# ASR6601 register map
Vendor: ASR Microelectronics; Series: ASR6601; File version: 1.1
CPU: CM4 r0p1, little endian, no MPU, FPU, VTOR, 3 interrupt priority bits
Registers are 32-bit, read-write, no defined reset value unless marked. A register's access mark holds for its fields unless they carry their own. Offsets are from the block's base; [hi:lo] are bit positions; {n}, {i} and the like mark numbered series.

## RCC — Reset and clock control
Base 0x40000000
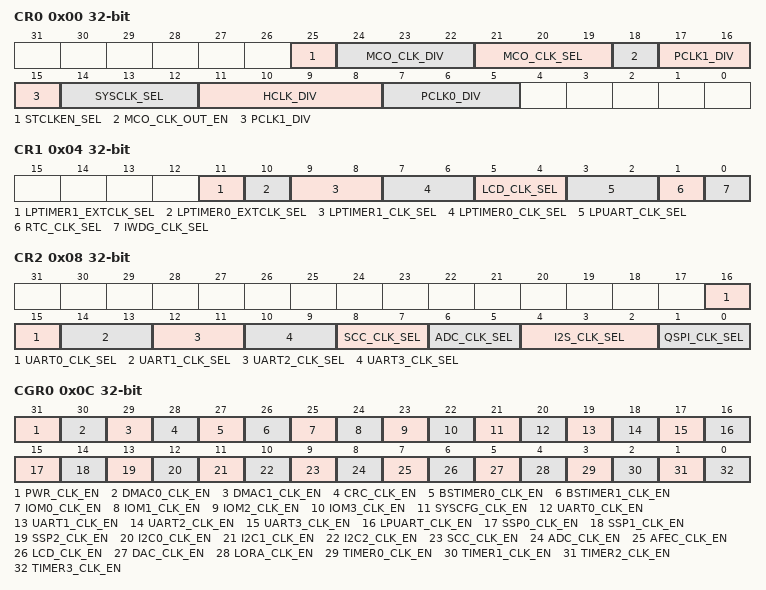
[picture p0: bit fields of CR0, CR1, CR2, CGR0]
0x00 CR0 — control register 0
  [25] STCLKEN_SEL
    1=RCO32K; 0=XO32K
  [24:22] MCO_CLK_DIV
    0=VALUE_1; 7=VALUE_16; 4=VALUE_2; 5=VALUE_4; 6=VALUE_8
  [21:19] MCO_CLK_SEL
    6=PLL; 0=RCO32K; 5=RCO48M; 2=RCO4M; 7=SYSCLCK; 3=XO24M; 1=XO32K; 4=XO32M
  [18] MCO_CLK_OUT_EN
  [17:15] PCLK1_DIV
    0=VALUE_1; 4=VALUE_16; 1=VALUE_2; 2=VALUE_4; 3=VALUE_8
  [14:12] SYSCLK_SEL
    3=PLL; 1=RCO32K; 7=RCO48M; 0=RCO48M_DIV2; 6=RCO4M; 4=XO24M; 2=XO32K; 5=XO32M
  [11:8] HCLK_DIV
    0=VALUE_1; 7=VALUE_128; 4=VALUE_16; 1=VALUE_2; 8=VALUE_256; 5=VALUE_32; 2=VALUE_4; 9=VALUE_512; 6=VALUE_64; 3=VALUE_8
  [7:5] PCLK0_DIV
    0=VALUE_1; 4=VALUE_16; 1=VALUE_2; 2=VALUE_4; 3=VALUE_8
0x04 CR1 — control register 1
  [11] LPTIMER1_EXTCLK_SEL
  [10] LPTIMER0_EXTCLK_SEL
  [9:8] LPTIMER1_CLK_SEL
    0=PCLK0; 3=RCO32K; 1=RCO4M; 2=XO32K
  [7:6] LPTIMER0_CLK_SEL
    0=PCLK0; 3=RCO32K; 1=RCO4M; 2=XO32K
  [5:4] LCD_CLK_SEL
    1=RCO32K; 2=RCO4M; 0=XO32K
  [3:2] LPUART_CLK_SEL
    1=RCO32K; 2=RCO4M; 0=XO32K
  [1] RTC_CLK_SEL
    1=RCO32K; 0=XO32K
  [0] IWDG_CLK_SEL
    1=RCO32K; 0=XO32K
0x08 CR2 — control register 2
  [16:15] UART0_CLK_SEL
    0=PCLK0; 1=RCO4M; 3=XO24M; 2=XO32K
  [14:13] UART1_CLK_SEL
    0=PCLK0; 1=RCO4M; 3=XO24M; 2=XO32K
  [12:11] UART2_CLK_SEL
    0=PCLK1; 1=RCO4M; 3=XO24M; 2=XO32K
  [10:9] UART3_CLK_SEL
    0=PCLK1; 1=RCO4M; 3=XO24M; 2=XO32K
  [8:7] SCC_CLK_SEL
    3=EXT; 0=PCLK1; 2=PLL; 1=SYSCLK
  [6:5] ADC_CLK_SEL
    0=PCLK1; 2=PLL; 3=RCO48M; 1=SYSCLK
  [4:2] I2S_CLK_SEL
    4=EXT_CLK; 0=PCLK0; 2=PLL; 1=XO24M; 3=XO32M
  [1:0] QSPI_CLK_SEL
    0=HCLK; 2=PLL; 1=SYSCLK
0x0C CGR0 — clock generation register 0
  [31] PWR_CLK_EN, [30] DMAC0_CLK_EN, [29] DMAC1_CLK_EN, [28] CRC_CLK_EN, [27] BSTIMER0_CLK_EN, [26] BSTIMER1_CLK_EN, [25-n] IOM{n}_CLK_EN (n=0..3), [21] SYSCFG_CLK_EN, [20-n] UART{n}_CLK_EN (n=0..3), [16] LPUART_CLK_EN, [15] SSP0_CLK_EN, [14] SSP1_CLK_EN, [13] SSP2_CLK_EN, [12] I2C0_CLK_EN, [11] I2C1_CLK_EN, [10] I2C2_CLK_EN, [9] SCC_CLK_EN, [8] ADC_CLK_EN, [7] AFEC_CLK_EN, [6] LCD_CLK_EN, [5] DAC_CLK_EN, [4] LORA_CLK_EN, [3-n] TIMER{n}_CLK_EN (n=0..3)
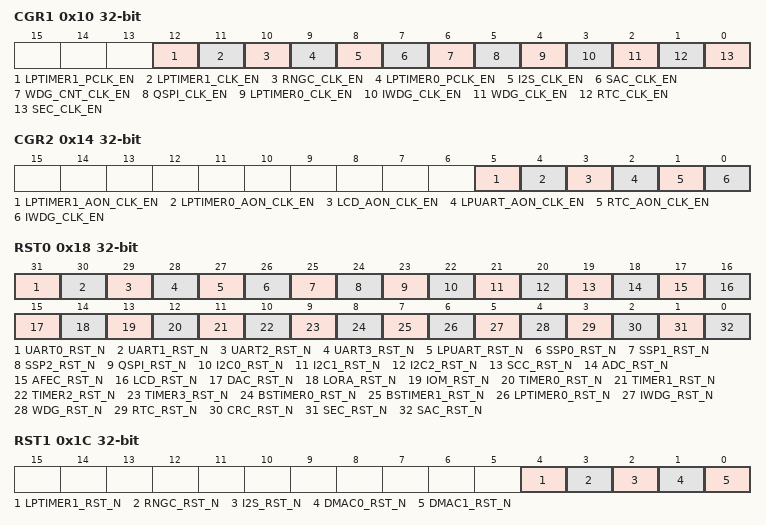
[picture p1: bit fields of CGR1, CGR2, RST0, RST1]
0x10 CGR1 — clock generation register 1
  [12] LPTIMER1_PCLK_EN, [11] LPTIMER1_CLK_EN, [10] RNGC_CLK_EN, [9] LPTIMER0_PCLK_EN, [8] I2S_CLK_EN, [7] SAC_CLK_EN, [6] WDG_CNT_CLK_EN, [5] QSPI_CLK_EN, [4] LPTIMER0_CLK_EN, [3] IWDG_CLK_EN, [2] WDG_CLK_EN, [1] RTC_CLK_EN, [0] SEC_CLK_EN
0x14 CGR2 — clock generation register 2
  [5] LPTIMER1_AON_CLK_EN, [4] LPTIMER0_AON_CLK_EN, [3] LCD_AON_CLK_EN, [2] LPUART_AON_CLK_EN, [1] RTC_AON_CLK_EN, [0] IWDG_CLK_EN
0x18 RST0 — reset register 0
  [31-n] UART{n}_RST_N (n=0..3), [27] LPUART_RST_N, [26] SSP0_RST_N, [25] SSP1_RST_N, [24] SSP2_RST_N, [23] QSPI_RST_N, [22] I2C0_RST_N, [21] I2C1_RST_N, [20] I2C2_RST_N, [19] SCC_RST_N, [18] ADC_RST_N, [17] AFEC_RST_N, [16] LCD_RST_N, [15] DAC_RST_N, [14] LORA_RST_N, [13] IOM_RST_N, [12-n] TIMER{n}_RST_N (n=0..3), [8] BSTIMER0_RST_N, [7] BSTIMER1_RST_N, [6] LPTIMER0_RST_N, [5] IWDG_RST_N, [4] WDG_RST_N, [3] RTC_RST_N, [2] CRC_RST_N, [1] SEC_RST_N, [0] SAC_RST_N
0x1C RST1 — reset register 1
  [4] LPTIMER1_RST_N, [3] RNGC_RST_N, [2] I2S_RST_N, [1] DMAC0_RST_N, [0] DMAC1_RST_N
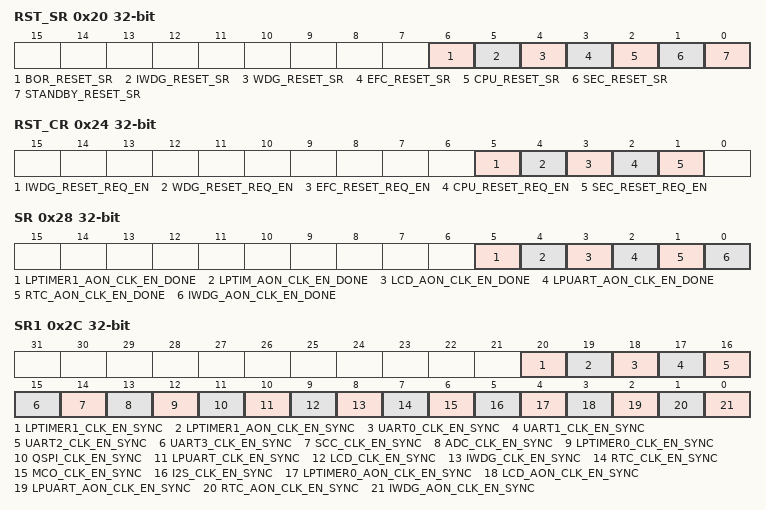
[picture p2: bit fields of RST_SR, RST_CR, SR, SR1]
0x20 RST_SR — reset status register 0
  [6] BOR_RESET_SR, [5] IWDG_RESET_SR, [4] WDG_RESET_SR, [3] EFC_RESET_SR, [2] CPU_RESET_SR, [1] SEC_RESET_SR, [0] STANDBY_RESET_SR
0x24 RST_CR — reset control register 0
  [5] IWDG_RESET_REQ_EN, [4] WDG_RESET_REQ_EN, [3] EFC_RESET_REQ_EN, [2] CPU_RESET_REQ_EN, [1] SEC_RESET_REQ_EN
0x28 SR ro — status register
  [5] LPTIMER1_AON_CLK_EN_DONE, [4] LPTIM_AON_CLK_EN_DONE, [3] LCD_AON_CLK_EN_DONE, [2] LPUART_AON_CLK_EN_DONE, [1] RTC_AON_CLK_EN_DONE, [0] IWDG_AON_CLK_EN_DONE
0x2C SR1 ro — status register 1
  [20] LPTIMER1_CLK_EN_SYNC, [19] LPTIMER1_AON_CLK_EN_SYNC, [18-n] UART{n}_CLK_EN_SYNC (n=0..3), [14] SCC_CLK_EN_SYNC, [13] ADC_CLK_EN_SYNC, [12] LPTIMER0_CLK_EN_SYNC, [11] QSPI_CLK_EN_SYNC, [10] LPUART_CLK_EN_SYNC, [9] LCD_CLK_EN_SYNC, [8] IWDG_CLK_EN_SYNC, [7] RTC_CLK_EN_SYNC, [6] MCO_CLK_EN_SYNC, [5] I2S_CLK_EN_SYNC, [4] LPTIMER0_AON_CLK_EN_SYNC, [3] LCD_AON_CLK_EN_SYNC, [2] LPUART_AON_CLK_EN_SYNC, [1] RTC_AON_CLK_EN_SYNC, [0] IWDG_AON_CLK_EN_SYNC
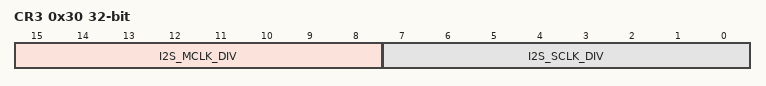
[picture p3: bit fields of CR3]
0x30 CR3 — control register 3
  [15:8] I2S_MCLK_DIV, [7:0] I2S_SCLK_DIV
